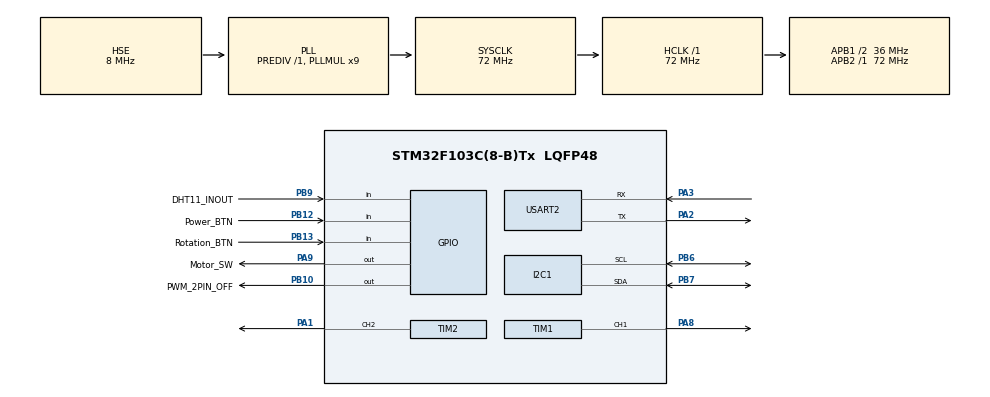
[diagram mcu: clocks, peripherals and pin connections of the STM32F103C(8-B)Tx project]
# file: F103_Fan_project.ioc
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FREERTOS.Tasks01=DHT11,0,128,DHT11Sensor,Default,NULL,Dynamic,NULL,NULL;Servo,-3,128,Servomotor,Default,NULL,Dynamic,NULL,NULL;LCDI2C,-3,128,LCD,Default,NULL,Dynamic,NULL,NULL;Motor,-3,128,MotorSpin,Default,NULL,Dynamic,NULL,NULL
FREERTOS.configUSE_NEWLIB_REENTRANT=1
Mcu.Family=STM32F1
Mcu.Name=STM32F103C(8-B)Tx
Mcu.Package=LQFP48
NVIC.PriorityGroup=NVIC_PRIORITYGROUP_4
NVIC.TIM3_IRQn=true\:15\:0\:false\:false\:true\:false\:false\:true\:true
NVIC.TimeBase=TIM3_IRQn
NVIC.TimeBaseIP=TIM3
NVIC.USART2_IRQn=true\:5\:0\:false\:false\:true\:true\:true\:true\:true
PA1.Signal=S_TIM2_CH2
PA13.Mode=Serial_Wire
PA13.Signal=SYS_JTMS-SWDIO
PA14.Mode=Serial_Wire
PA14.Signal=SYS_JTCK-SWCLK
PA2.Mode=Asynchronous
PA2.Signal=USART2_TX
PA3.Mode=Asynchronous
PA3.Signal=USART2_RX
PA8.Signal=S_TIM1_CH1
PA9.GPIO_Label=Motor_SW
PA9.GPIO_ModeDefaultOutputPP=GPIO_MODE_OUTPUT_PP
PA9.Signal=GPIO_Output
PB10.GPIO_Label=PWM_2PIN_OFF
PB10.Signal=GPIO_Output
PB12.GPIO_Label=Power_BTN
PB12.GPIO_PuPd=GPIO_PULLUP
PB12.Signal=GPIO_Input
PB13.GPIO_Label=Rotation_BTN
PB13.GPIO_PuPd=GPIO_PULLUP
PB13.Signal=GPIO_Input
PB6.Mode=I2C
PB6.Signal=I2C1_SCL
PB7.Mode=I2C
PB7.Signal=I2C1_SDA
PB9.GPIO_Label=DHT11_INOUT
PB9.Signal=GPIO_Input
PD0-OSC_IN.Mode=HSE-External-Oscillator
PD0-OSC_IN.Signal=RCC_OSC_IN
PD1-OSC_OUT.Mode=HSE-External-Oscillator
PD1-OSC_OUT.Signal=RCC_OSC_OUT
ProjectManager.HeapSize=0x200
ProjectManager.StackSize=0x400
ProjectManager.TargetToolchain=STM32CubeIDE
RCC.AHBFreq_Value=72000000
RCC.APB1CLKDivider=RCC_HCLK_DIV2
RCC.APB1Freq_Value=36000000
RCC.APB1TimFreq_Value=72000000
RCC.APB2Freq_Value=72000000
RCC.APB2TimFreq_Value=72000000
RCC.HCLKFreq_Value=72000000
RCC.PLLMUL=RCC_PLL_MUL9
RCC.PLLSourceVirtual=RCC_PLLSOURCE_HSE
RCC.SYSCLKFreq_VALUE=72000000
RCC.SYSCLKSource=RCC_SYSCLKSOURCE_PLLCLK
RCC.USBFreq_Value=72000000
SH.S_TIM1_CH1.0=TIM1_CH1,PWM Generation1 CH1
SH.S_TIM2_CH2.0=TIM2_CH2,PWM Generation2 CH2
TIM1.Channel-PWM\ Generation1\ CH1=TIM_CHANNEL_1
TIM1.Period=1000-1
TIM1.Prescaler=1000-1
TIM2.Channel-PWM\ Generation2\ CH2=TIM_CHANNEL_2
TIM2.Period=20000 - 1
TIM2.Prescaler=72-1
TIM4.Prescaler=72-1
USART2.VirtualMode=VM_ASYNC
VP_FREERTOS_VS_CMSIS_V1.Mode=CMSIS_V1
VP_SYS_VS_tim3.Mode=TIM3
VP_TIM4_VS_ClockSourceINT.Mode=Internal
board=custom

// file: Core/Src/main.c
/* USER CODE BEGIN Header */
/**
  ******************************************************************************
  * @file           : main.c
  * @brief          : Main program body
  ******************************************************************************
  * @attention
  *
  * Copyright (c) 2024 STMicroelectronics.
  * All rights reserved.
  *
  * This software is licensed under terms that can be found in the LICENSE file
  * in the root directory of this software component.
  * If no LICENSE file comes with this software, it is provided AS-IS.
  *
  ******************************************************************************
  */
/* USER CODE END Header */
#include "main.h"
#include "cmsis_os.h"
#include "stdio.h"

/* USER CODE BEGIN PD */
#define SERVO_MIN_PULSE 500
#define SERVO_MAX_PULSE 2500

#define SLAVE_ADDRESS_LCD 0x4E

#define DHT11_PORT GPIOB
#define DHT11_PIN GPIO_PIN_9
/* USER CODE END PD */

/* USER CODE BEGIN PM */
uint16_t PWM_duty = 0;
uint8_t motor_level = 0;
uint8_t current_button_state = 0;
uint8_t previous_button_state = 0;

uint8_t servo_level = 0;
uint8_t current_button_servo_state = 0;
uint8_t previous_button_servo_state = 0;
uint8_t angle = 68;
uint8_t increment = 1;

uint16_t SUM, RH, TEMP;
uint8_t Temperature = 0;
uint8_t Humidity = 0;
uint8_t Presence = 0;
uint8_t Rh_byte1, Rh_byte2, Temp_byte1, Temp_byte2;

uint8_t lcd_update_flag = 0;
/* USER CODE END PM */

I2C_HandleTypeDef hi2c1;

TIM_HandleTypeDef htim1;
TIM_HandleTypeDef htim2;
TIM_HandleTypeDef htim4;

UART_HandleTypeDef huart2;

osThreadId DHT11Handle;
osThreadId ServoHandle;
osThreadId LCDI2CHandle;
osThreadId MotorHandle;

void SystemClock_Config(void);
static void MX_GPIO_Init(void);
static void MX_TIM1_Init(void);
static void MX_I2C1_Init(void);
static void MX_TIM2_Init(void);
static void MX_USART2_UART_Init(void);
static void MX_TIM4_Init(void);
void DHT11Sensor(void const * argument);
void Servomotor(void const * argument);
void LCD(void const * argument);
void MotorSpin(void const * argument);

/* USER CODE BEGIN PFP */
void delay_us (uint16_t us)
{
    __HAL_TIM_SET_COUNTER(&htim4, 0);
    while ((__HAL_TIM_GET_COUNTER(&htim4))<us);
}

void PWM_Init(void)
{
    HAL_TIM_PWM_Start(&htim1, TIM_CHANNEL_1);
}

void PWM_Speed(uint16_t CCR)
{
    __HAL_TIM_SET_COMPARE(&htim1, TIM_CHANNEL_1, CCR);
}

void PWM_Set_Motor_Speed_Level(uint8_t level)
{
    switch (level)
    {
        case 0:
            PWM_duty = 0;    // Stop
            break;
        case 1:
            PWM_duty = 250;  // Low speed
            break;
        case 2:
            PWM_duty = 500;  // Medium speed
            break;
        case 3:
            PWM_duty = 750;  // High speed
            break;
    }
    PWM_Speed(PWM_duty); // Apply PWM duty cycle
}

void lcd_send_cmd (char cmd)
{
  char data_u, data_l;
	uint8_t data_t[4];
	data_u = (cmd&0xf0);
	data_l = ((cmd<<4)&0xf0);
	data_t[0] = data_u|0x0C;  //en=1, rs=0
	data_t[1] = data_u|0x08;  //en=0, rs=0
	data_t[2] = data_l|0x0C;  //en=1, rs=0
	data_t[3] = data_l|0x08;  //en=0, rs=0
	HAL_I2C_Master_Transmit (&hi2c1, SLAVE_ADDRESS_LCD,(uint8_t *) data_t, 4, 100);
}

void lcd_send_data (char data)
{
	char data_u, data_l;
	uint8_t data_t[4];
	data_u = (data&0xf0);
	data_l = ((data<<4)&0xf0);
	data_t[0] = data_u|0x0D;  //en=1, rs=0
	data_t[1] = data_u|0x09;  //en=0, rs=0
	data_t[2] = data_l|0x0D;  //en=1, rs=0
	data_t[3] = data_l|0x09;  //en=0, rs=0
	HAL_I2C_Master_Transmit (&hi2c1, SLAVE_ADDRESS_LCD,(uint8_t *) data_t, 4, 100);
}

void lcd_clear (void)
{
	lcd_send_cmd(0x01);
	delay_us(10000);
}

void lcd_put_cur(int row, int col)
{
    switch (row)
    {
        case 0:
            col |= 0x80;
            break;
        case 1:
            col |= 0xC0;
            break;
    }

    lcd_send_cmd (col);
}

void lcd_init(void)
{
	// 4 bit initialisation
	delay_us(45000);  // wait for >40ms
	lcd_send_cmd (0x30);
	delay_us(4200);  // wait for >4.1ms
	lcd_send_cmd (0x30);
	delay_us(120);  // wait for >100us
	lcd_send_cmd (0x30);
	delay_us(10000);
	lcd_send_cmd (0x20);  // 4bit mode
	delay_us(10000);

  // dislay initialisation
	lcd_send_cmd (0x28); // Function set --> DL=0 (4 bit mode), N = 1 (2 line display) F = 0 (5x8 characters)
	delay_us(1000);
	lcd_send_cmd (0x08); //Display on/off control --> D=0,C=0, B=0  ---> display off
	delay_us(1000);
	lcd_send_cmd (0x01);  // clear display
	delay_us(2000);
	lcd_send_cmd (0x06); //Entry mode set --> I/D = 1 (increment cursor) & S = 0 (no shift)
	delay_us(1000);
	lcd_send_cmd (0x0C); //Display on/off control --> D = 1, C and B = 0. (Cursor and blink, last two bits)
}

void lcd_send_string (char *str)
{
	while (*str) lcd_send_data (*str++);
}

void lcd_update_status()
{
    lcd_clear();  // 화면을 지워 이전 텍스트 제거

    char motor_status[10];
    sprintf(motor_status, "POW:%d  ", motor_level);

    char servo_status[10];
    if (servo_level == 1)
        sprintf(servo_status, "ROT:ON ");
    else
        sprintf(servo_status, "ROT:OFF");

    char temp_status[10];  // 버퍼 크기 늘리기
    sprintf(temp_status, "TEMP:%dC", Temperature);

    char humi_status[10];  // 버퍼 크기 늘리기
    sprintf(humi_status, "HUMI:%d%%", Humidity);

    lcd_put_cur(0, 0);
    lcd_send_string(motor_status);
    lcd_put_cur(0, 8);
    lcd_send_string(temp_status);

    lcd_put_cur(1, 0);
    lcd_send_string(servo_status);
    lcd_put_cur(1, 8);
    lcd_send_string(humi_status);
}

void check_and_initialize_lcd()
{
	lcd_update_status();
}

void Servo_Set_Angle(uint16_t angle) {
    if (angle > 180) angle = 180;
    if (angle < 0) angle = 0;
    uint16_t pulse_length = SERVO_MIN_PULSE + ((SERVO_MAX_PULSE - SERVO_MIN_PULSE) * angle) / 180;
    __HAL_TIM_SET_COMPARE(&htim2, TIM_CHANNEL_2, pulse_length);
}

void DHT11_SetPin_Output(void)
{
    GPIO_InitTypeDef GPIO_InitStruct = {0};
    GPIO_InitStruct.Pin = DHT11_PIN;
    GPIO_InitStruct.Mode = GPIO_MODE_OUTPUT_PP;
    GPIO_InitStruct.Speed = GPIO_SPEED_FREQ_LOW;
    HAL_GPIO_Init(DHT11_PORT, &GPIO_InitStruct);
}

// Set DHT11 pin as input
void DHT11_SetPin_Input(void)
{
    GPIO_InitTypeDef GPIO_InitStruct = {0};
    GPIO_InitStruct.Pin = DHT11_PIN;
    GPIO_InitStruct.Mode = GPIO_MODE_INPUT;
    GPIO_InitStruct.Pull = GPIO_NOPULL;
    HAL_GPIO_Init(DHT11_PORT, &GPIO_InitStruct);
}

// Start signal to DHT11
void DHT11_Start(void)
{
    DHT11_SetPin_Output();
    HAL_GPIO_WritePin(DHT11_PORT, DHT11_PIN, GPIO_PIN_RESET);  // Pull low for 18 ms
    HAL_Delay(18);
    HAL_GPIO_WritePin(DHT11_PORT, DHT11_PIN, GPIO_PIN_SET);  // Pull high for 20-40 us
    delay_us(20);
    DHT11_SetPin_Input();  // Set as input for DHT11 response
}

// Check DHT11 response
uint8_t DHT11_Check_Response(void)
{
    uint8_t response = 0;
    delay_us(40);
    if (!(HAL_GPIO_ReadPin(DHT11_PORT, DHT11_PIN)))
    {
        delay_us(80);
        if ((HAL_GPIO_ReadPin(DHT11_PORT, DHT11_PIN))) response = 1;
        else response = -1;
    }
    while ((HAL_GPIO_ReadPin(DHT11_PORT, DHT11_PIN)));  // Wait for pin to go low
    return response;
}

// Read one byte from DHT11
uint8_t DHT11_Read(void)
{
    uint8_t i, j;
    for (j = 0; j < 8; j++)
    {
        while (!(HAL_GPIO_ReadPin(DHT11_PORT, DHT11_PIN)));  // Wait for pin to go high
        delay_us(40);
        if (!(HAL_GPIO_ReadPin(DHT11_PORT, DHT11_PIN))) // If pin is low after 40 us, it’s a 0
        {
            i &= ~(1 << (7 - j));  // Write 0
        }
        else i |= (1 << (7 - j));  // If pin is high after 40 us, it’s a 1
        while ((HAL_GPIO_ReadPin(DHT11_PORT, DHT11_PIN)));  // Wait for pin to go low
    }
    return i;
}

// Get temperature and humidity from DHT11
void DHT11_GetData(uint8_t *temperature, uint8_t *humidity)
{
    DHT11_Start();
    Presence = DHT11_Check_Response();
    Rh_byte1 = DHT11_Read();
    Rh_byte2 = DHT11_Read();
    Temp_byte1 = DHT11_Read();
    Temp_byte2 = DHT11_Read();
    SUM = DHT11_Read();

    // Checksum verification
    if (SUM == (Rh_byte1 + Rh_byte2 + Temp_byte1 + Temp_byte2))
    {
        *temperature = Temp_byte1;
        *humidity = Rh_byte1;
    }
    else
    {
        *temperature = 0;  // Error value if checksum fails
        *humidity = 0;
    }
}

/* USER CODE END PFP */

int main(void)
{

  /* MCU Configuration--------------------------------------------------------*/

  /* Reset of all peripherals, Initializes the Flash interface and the Systick. */
  HAL_Init();

  /* Configure the system clock */
  SystemClock_Config();

  /* Initialize all configured peripherals */
  MX_GPIO_Init();
  MX_TIM1_Init();
  MX_I2C1_Init();
  MX_TIM2_Init();
  MX_USART2_UART_Init();
  MX_TIM4_Init();
  /* USER CODE BEGIN 2 */

  HAL_TIM_PWM_Start(&htim1, TIM_CHANNEL_1);
  HAL_TIM_PWM_Start(&htim2, TIM_CHANNEL_2);
  HAL_TIM_Base_Start(&htim4);

  /* USER CODE END 2 */

  /* Create the thread(s) */
  /* definition and creation of DHT11 */
  osThreadDef(DHT11, DHT11Sensor, osPriorityNormal, 0, 128);
  DHT11Handle = osThreadCreate(osThread(DHT11), NULL);

  /* definition and creation of Servo */
  osThreadDef(Servo, Servomotor, osPriorityIdle, 0, 128);
  ServoHandle = osThreadCreate(osThread(Servo), NULL);

  /* definition and creation of LCDI2C */
  osThreadDef(LCDI2C, LCD, osPriorityIdle, 0, 128);
  LCDI2CHandle = osThreadCreate(osThread(LCDI2C), NULL);

  /* definition and creation of Motor */
  osThreadDef(Motor, MotorSpin, osPriorityIdle, 0, 128);
  MotorHandle = osThreadCreate(osThread(Motor), NULL);

  /* Start scheduler */
  osKernelStart();

  /* We should never get here as control is now taken by the scheduler */

  /* Infinite loop */
  while (1)
  {

  }
}

void SystemClock_Config(void)
{
  RCC_OscInitTypeDef RCC_OscInitStruct = {0};
  RCC_ClkInitTypeDef RCC_ClkInitStruct = {0};

  /** Initializes the RCC Oscillators according to the specified parameters
  * in the RCC_OscInitTypeDef structure.
  */
  RCC_OscInitStruct.OscillatorType = RCC_OSCILLATORTYPE_HSE;
  RCC_OscInitStruct.HSEState = RCC_HSE_ON;
  RCC_OscInitStruct.HSEPredivValue = RCC_HSE_PREDIV_DIV1;
  RCC_OscInitStruct.HSIState = RCC_HSI_ON;
  RCC_OscInitStruct.PLL.PLLState = RCC_PLL_ON;
  RCC_OscInitStruct.PLL.PLLSource = RCC_PLLSOURCE_HSE;
  RCC_OscInitStruct.PLL.PLLMUL = RCC_PLL_MUL9;
  if (HAL_RCC_OscConfig(&RCC_OscInitStruct) != HAL_OK)
  {
    Error_Handler();
  }

  /** Initializes the CPU, AHB and APB buses clocks
  */
  RCC_ClkInitStruct.ClockType = RCC_CLOCKTYPE_HCLK|RCC_CLOCKTYPE_SYSCLK
                              |RCC_CLOCKTYPE_PCLK1|RCC_CLOCKTYPE_PCLK2;
  RCC_ClkInitStruct.SYSCLKSource = RCC_SYSCLKSOURCE_PLLCLK;
  RCC_ClkInitStruct.AHBCLKDivider = RCC_SYSCLK_DIV1;
  RCC_ClkInitStruct.APB1CLKDivider = RCC_HCLK_DIV2;
  RCC_ClkInitStruct.APB2CLKDivider = RCC_HCLK_DIV1;

  if (HAL_RCC_ClockConfig(&RCC_ClkInitStruct, FLASH_LATENCY_2) != HAL_OK)
  {
    Error_Handler();
  }
}

static void MX_I2C1_Init(void)
{

  hi2c1.Instance = I2C1;
  hi2c1.Init.ClockSpeed = 100000;
  hi2c1.Init.DutyCycle = I2C_DUTYCYCLE_2;
  hi2c1.Init.OwnAddress1 = 0;
  hi2c1.Init.AddressingMode = I2C_ADDRESSINGMODE_7BIT;
  hi2c1.Init.DualAddressMode = I2C_DUALADDRESS_DISABLE;
  hi2c1.Init.OwnAddress2 = 0;
  hi2c1.Init.GeneralCallMode = I2C_GENERALCALL_DISABLE;
  hi2c1.Init.NoStretchMode = I2C_NOSTRETCH_DISABLE;
  if (HAL_I2C_Init(&hi2c1) != HAL_OK)
  {
    Error_Handler();
  }

}

static void MX_TIM1_Init(void)
{

  TIM_MasterConfigTypeDef sMasterConfig = {0};
  TIM_OC_InitTypeDef sConfigOC = {0};
  TIM_BreakDeadTimeConfigTypeDef sBreakDeadTimeConfig = {0};

  htim1.Instance = TIM1;
  htim1.Init.Prescaler = 1000-1;
  htim1.Init.CounterMode = TIM_COUNTERMODE_UP;
  htim1.Init.Period = 1000-1;
  htim1.Init.ClockDivision = TIM_CLOCKDIVISION_DIV1;
  htim1.Init.RepetitionCounter = 0;
  htim1.Init.AutoReloadPreload = TIM_AUTORELOAD_PRELOAD_DISABLE;
  if (HAL_TIM_PWM_Init(&htim1) != HAL_OK)
  {
    Error_Handler();
  }
  sMasterConfig.MasterOutputTrigger = TIM_TRGO_RESET;
  sMasterConfig.MasterSlaveMode = TIM_MASTERSLAVEMODE_DISABLE;
  if (HAL_TIMEx_MasterConfigSynchronization(&htim1, &sMasterConfig) != HAL_OK)
  {
    Error_Handler();
  }
  sConfigOC.OCMode = TIM_OCMODE_PWM1;
  sConfigOC.Pulse = 0;
  sConfigOC.OCPolarity = TIM_OCPOLARITY_HIGH;
  sConfigOC.OCNPolarity = TIM_OCNPOLARITY_HIGH;
  sConfigOC.OCFastMode = TIM_OCFAST_DISABLE;
  sConfigOC.OCIdleState = TIM_OCIDLESTATE_RESET;
  sConfigOC.OCNIdleState = TIM_OCNIDLESTATE_RESET;
  if (HAL_TIM_PWM_ConfigChannel(&htim1, &sConfigOC, TIM_CHANNEL_1) != HAL_OK)
  {
    Error_Handler();
  }
  sBreakDeadTimeConfig.OffStateRunMode = TIM_OSSR_DISABLE;
  sBreakDeadTimeConfig.OffStateIDLEMode = TIM_OSSI_DISABLE;
  sBreakDeadTimeConfig.LockLevel = TIM_LOCKLEVEL_OFF;
  sBreakDeadTimeConfig.DeadTime = 0;
  sBreakDeadTimeConfig.BreakState = TIM_BREAK_DISABLE;
  sBreakDeadTimeConfig.BreakPolarity = TIM_BREAKPOLARITY_HIGH;
  sBreakDeadTimeConfig.AutomaticOutput = TIM_AUTOMATICOUTPUT_DISABLE;
  if (HAL_TIMEx_ConfigBreakDeadTime(&htim1, &sBreakDeadTimeConfig) != HAL_OK)
  {
    Error_Handler();
  }
  HAL_TIM_MspPostInit(&htim1);

}

static void MX_TIM2_Init(void)
{

  TIM_MasterConfigTypeDef sMasterConfig = {0};
  TIM_OC_InitTypeDef sConfigOC = {0};

  htim2.Instance = TIM2;
  htim2.Init.Prescaler = 72-1;
  htim2.Init.CounterMode = TIM_COUNTERMODE_UP;
  htim2.Init.Period = 20000 - 1;
  htim2.Init.ClockDivision = TIM_CLOCKDIVISION_DIV1;
  htim2.Init.AutoReloadPreload = TIM_AUTORELOAD_PRELOAD_DISABLE;
  if (HAL_TIM_PWM_Init(&htim2) != HAL_OK)
  {
    Error_Handler();
  }
  sMasterConfig.MasterOutputTrigger = TIM_TRGO_RESET;
  sMasterConfig.MasterSlaveMode = TIM_MASTERSLAVEMODE_DISABLE;
  if (HAL_TIMEx_MasterConfigSynchronization(&htim2, &sMasterConfig) != HAL_OK)
  {
    Error_Handler();
  }
  sConfigOC.OCMode = TIM_OCMODE_PWM1;
  sConfigOC.Pulse = 0;
  sConfigOC.OCPolarity = TIM_OCPOLARITY_HIGH;
  sConfigOC.OCFastMode = TIM_OCFAST_DISABLE;
  if (HAL_TIM_PWM_ConfigChannel(&htim2, &sConfigOC, TIM_CHANNEL_2) != HAL_OK)
  {
    Error_Handler();
  }
  HAL_TIM_MspPostInit(&htim2);

}

static void MX_TIM4_Init(void)
{

  TIM_ClockConfigTypeDef sClockSourceConfig = {0};
  TIM_MasterConfigTypeDef sMasterConfig = {0};

  htim4.Instance = TIM4;
  htim4.Init.Prescaler = 72-1;
  htim4.Init.CounterMode = TIM_COUNTERMODE_UP;
  htim4.Init.Period = 65535;
  htim4.Init.ClockDivision = TIM_CLOCKDIVISION_DIV1;
  htim4.Init.AutoReloadPreload = TIM_AUTORELOAD_PRELOAD_DISABLE;
  if (HAL_TIM_Base_Init(&htim4) != HAL_OK)
  {
    Error_Handler();
  }
  sClockSourceConfig.ClockSource = TIM_CLOCKSOURCE_INTERNAL;
  if (HAL_TIM_ConfigClockSource(&htim4, &sClockSourceConfig) != HAL_OK)
  {
    Error_Handler();
  }
  sMasterConfig.MasterOutputTrigger = TIM_TRGO_RESET;
  sMasterConfig.MasterSlaveMode = TIM_MASTERSLAVEMODE_DISABLE;
  if (HAL_TIMEx_MasterConfigSynchronization(&htim4, &sMasterConfig) != HAL_OK)
  {
    Error_Handler();
  }

}

static void MX_USART2_UART_Init(void)
{

  huart2.Instance = USART2;
  huart2.Init.BaudRate = 115200;
  huart2.Init.WordLength = UART_WORDLENGTH_8B;
  huart2.Init.StopBits = UART_STOPBITS_1;
  huart2.Init.Parity = UART_PARITY_NONE;
  huart2.Init.Mode = UART_MODE_TX_RX;
  huart2.Init.HwFlowCtl = UART_HWCONTROL_NONE;
  huart2.Init.OverSampling = UART_OVERSAMPLING_16;
  if (HAL_UART_Init(&huart2) != HAL_OK)
  {
    Error_Handler();
  }

}

static void MX_GPIO_Init(void)
{
  GPIO_InitTypeDef GPIO_InitStruct = {0};

  /* GPIO Ports Clock Enable */
  __HAL_RCC_GPIOC_CLK_ENABLE();
  __HAL_RCC_GPIOD_CLK_ENABLE();
  __HAL_RCC_GPIOA_CLK_ENABLE();
  __HAL_RCC_GPIOB_CLK_ENABLE();

  /*Configure GPIO pin Output Level */
  HAL_GPIO_WritePin(GPIOC, GPIO_PIN_13, GPIO_PIN_RESET);

  /*Configure GPIO pin Output Level */
  HAL_GPIO_WritePin(PWM_2PIN_OFF_GPIO_Port, PWM_2PIN_OFF_Pin, GPIO_PIN_RESET);

  /*Configure GPIO pin Output Level */
  HAL_GPIO_WritePin(Motor_SW_GPIO_Port, Motor_SW_Pin, GPIO_PIN_RESET);

  /*Configure GPIO pin : PC13 */
  GPIO_InitStruct.Pin = GPIO_PIN_13;
  GPIO_InitStruct.Mode = GPIO_MODE_OUTPUT_PP;
  GPIO_InitStruct.Pull = GPIO_NOPULL;
  GPIO_InitStruct.Speed = GPIO_SPEED_FREQ_LOW;
  HAL_GPIO_Init(GPIOC, &GPIO_InitStruct);

  /*Configure GPIO pin : PWM_2PIN_OFF_Pin */
  GPIO_InitStruct.Pin = PWM_2PIN_OFF_Pin;
  GPIO_InitStruct.Mode = GPIO_MODE_OUTPUT_PP;
  GPIO_InitStruct.Pull = GPIO_NOPULL;
  GPIO_InitStruct.Speed = GPIO_SPEED_FREQ_LOW;
  HAL_GPIO_Init(PWM_2PIN_OFF_GPIO_Port, &GPIO_InitStruct);

  /*Configure GPIO pins : Power_BTN_Pin Rotation_BTN_Pin */
  GPIO_InitStruct.Pin = Power_BTN_Pin|Rotation_BTN_Pin;
  GPIO_InitStruct.Mode = GPIO_MODE_INPUT;
  GPIO_InitStruct.Pull = GPIO_PULLUP;
  HAL_GPIO_Init(GPIOB, &GPIO_InitStruct);

  /*Configure GPIO pin : Motor_SW_Pin */
  GPIO_InitStruct.Pin = Motor_SW_Pin;
  GPIO_InitStruct.Mode = GPIO_MODE_OUTPUT_PP;
  GPIO_InitStruct.Pull = GPIO_NOPULL;
  GPIO_InitStruct.Speed = GPIO_SPEED_FREQ_LOW;
  HAL_GPIO_Init(Motor_SW_GPIO_Port, &GPIO_InitStruct);

}

void DHT11Sensor(void const * argument)
{
  /* USER CODE BEGIN 5 */
  /* Infinite loop */
  for(;;)
  {
	  DHT11_GetData(&Temperature, &Humidity);
      lcd_update_flag = 2;
      osDelay(4000);  // 2초마다 센서 데이터 갱신
  }
  /* USER CODE END 5 */
}

void Servomotor(void const * argument)
{
  /* USER CODE BEGIN Servomotor */
  Servo_Set_Angle(angle);
  /* Infinite loop */
  for(;;)
  {
      //Servo_start
      current_button_servo_state = (HAL_GPIO_ReadPin(GPIOB, GPIO_PIN_13) == GPIO_PIN_RESET) ? 1 : 0;
      if (current_button_servo_state == 1 && previous_button_servo_state == 0 && motor_level > 0)
      {
          servo_level = (servo_level + 1) % 2;
          lcd_update_flag = 2;
      }
      previous_button_servo_state = current_button_servo_state;

      //Servo_Angle
      if (servo_level == 1)
      {
          Servo_Set_Angle(angle);
          angle += increment;

          if (angle >= 130)
          {
              increment = -1;
          }
          if (angle <= 30)
          {
              increment = 1;
          }
      }
      osDelay(50);
  }
  /* USER CODE END Servomotor */
}

void LCD(void const * argument)
{
  /* USER CODE BEGIN LCD */
  lcd_init();
  /* Infinite loop */
  for(;;)
  {
	  if (lcd_update_flag == 0)
	  {
		  check_and_initialize_lcd();
		  lcd_update_flag = 1;
	  }

	  if (lcd_update_flag == 2)
	  {
		  check_and_initialize_lcd();
		  lcd_update_flag = 1;
	  }

    osDelay(1);
  }
  /* USER CODE END LCD */
}

void MotorSpin(void const * argument)
{
  /* USER CODE BEGIN MotorSpin */

  /* Infinite loop */
  for(;;)
  {
	  PWM_Init();

	  //Motor_1
      current_button_state = (HAL_GPIO_ReadPin(GPIOB, GPIO_PIN_12) == GPIO_PIN_SET) ? 0 : 1;
      if (current_button_state == 1 && previous_button_state == 0)
      {
          motor_level = (motor_level + 1) % 4;
          lcd_update_flag = 2;

          PWM_Set_Motor_Speed_Level(motor_level);
//          if (motor_level > 0)
//          {
//        	  check_and_initialize_lcd();
//          }
          if (motor_level == 0)
          {
        	  servo_level = 0;
        	  current_button_servo_state = 0;
        	  previous_button_servo_state = 0;
        	  lcd_update_flag = 0;
          }
      }
      previous_button_state = current_button_state;

    osDelay(50);
  }
  /* USER CODE END MotorSpin */
}

void HAL_TIM_PeriodElapsedCallback(TIM_HandleTypeDef *htim)
{
  if (htim->Instance == TIM3) {
    HAL_IncTick();
  }
}

void Error_Handler(void)
{
  __disable_irq();
  while (1)
  {
  }
}
